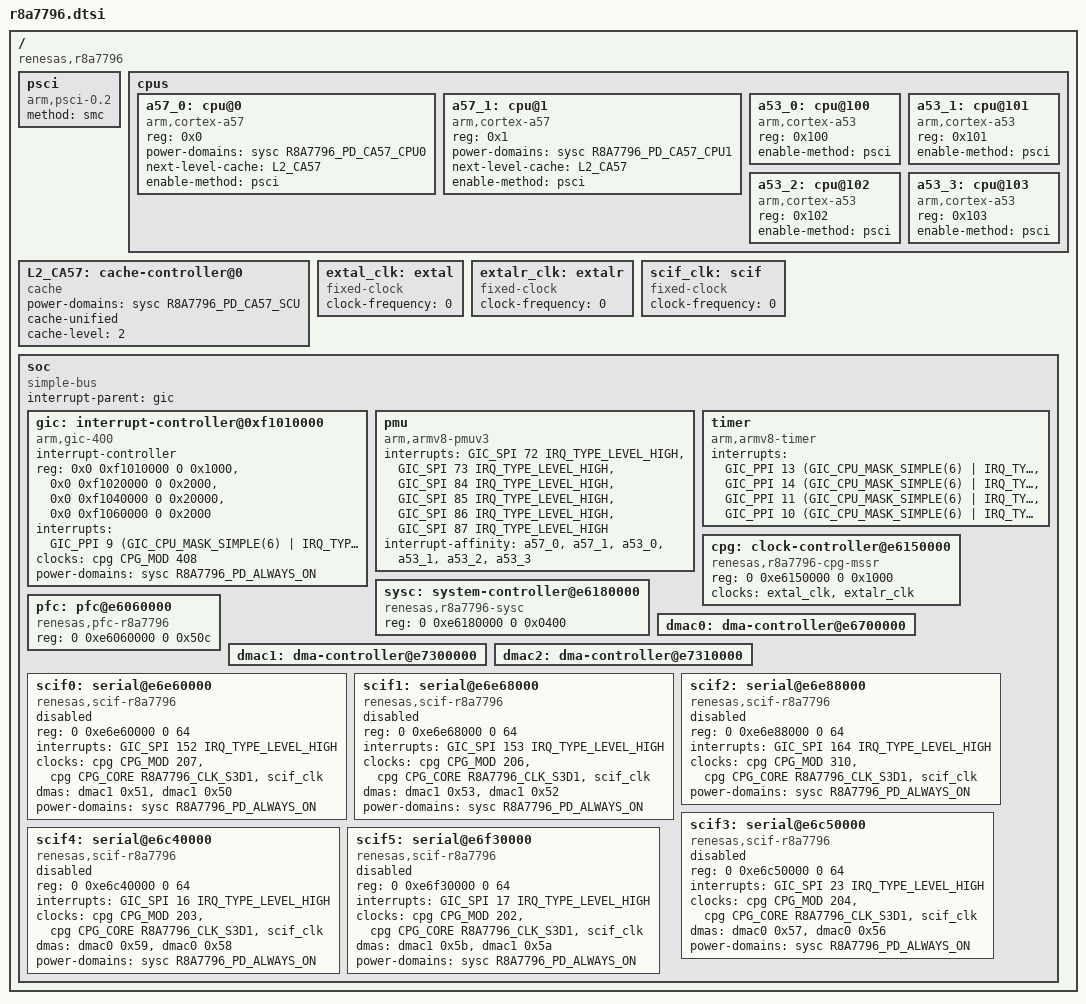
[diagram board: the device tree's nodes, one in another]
/*
 * Device Tree Source for the r8a7796 SoC
 *
 * Copyright (C) 2016 Renesas Electronics Corp.
 *
 * This file is licensed under the terms of the GNU General Public License
 * version 2.  This program is licensed "as is" without any warranty of any
 * kind, whether express or implied.
 */

#include <dt-bindings/clock/r8a7796-cpg-mssr.h>
#include <dt-bindings/interrupt-controller/arm-gic.h>
#include <dt-bindings/power/r8a7796-sysc.h>

/ {
	compatible = "renesas,r8a7796";
	#address-cells = <2>;
	#size-cells = <2>;

	psci {
		compatible = "arm,psci-0.2";
		method = "smc";
	};

	cpus {
		#address-cells = <1>;
		#size-cells = <0>;

		a57_0: cpu@0 {
			compatible = "arm,cortex-a57", "arm,armv8";
			reg = <0x0>;
			device_type = "cpu";
			power-domains = <&sysc R8A7796_PD_CA57_CPU0>;
			next-level-cache = <&L2_CA57>;
			enable-method = "psci";
		};

		a57_1: cpu@1 {
			compatible = "arm,cortex-a57","arm,armv8";
			reg = <0x1>;
			device_type = "cpu";
			power-domains = <&sysc R8A7796_PD_CA57_CPU1>;
			next-level-cache = <&L2_CA57>;
			enable-method = "psci";
		};

		a53_0: cpu@100 {
			compatible = "arm,cortex-a53", "arm,armv8";
			reg = <0x100>;
			device_type = "cpu";
			enable-method = "psci";
		};

		a53_1: cpu@101 {
			compatible = "arm,cortex-a53","arm,armv8";
			reg = <0x101>;
			device_type = "cpu";
			enable-method = "psci";
		};

		a53_2: cpu@102 {
			compatible = "arm,cortex-a53","arm,armv8";
			reg = <0x102>;
			device_type = "cpu";
			enable-method = "psci";
		};

		a53_3: cpu@103 {
			compatible = "arm,cortex-a53","arm,armv8";
			reg = <0x103>;
			device_type = "cpu";
			enable-method = "psci";
		};
	};

	L2_CA57: cache-controller@0 {
		compatible = "cache";
		power-domains = <&sysc R8A7796_PD_CA57_SCU>;
		cache-unified;
		cache-level = <2>;
	};

	extal_clk: extal {
		compatible = "fixed-clock";
		#clock-cells = <0>;
		/* This value must be overridden by the board */
		clock-frequency = <0>;
	};

	extalr_clk: extalr {
		compatible = "fixed-clock";
		#clock-cells = <0>;
		/* This value must be overridden by the board */
		clock-frequency = <0>;
	};

	/* External SCIF clock - to be overridden by boards that provide it */
	scif_clk: scif {
		compatible = "fixed-clock";
		#clock-cells = <0>;
		clock-frequency = <0>;
	};

	soc {
		compatible = "simple-bus";
		interrupt-parent = <&gic>;

		#address-cells = <2>;
		#size-cells = <2>;
		ranges;

		gic: interrupt-controller@0xf1010000 {
			compatible = "arm,gic-400";
			#interrupt-cells = <3>;
			#address-cells = <0>;
			interrupt-controller;
			reg = <0x0 0xf1010000 0 0x1000>,
			      <0x0 0xf1020000 0 0x2000>,
			      <0x0 0xf1040000 0 0x20000>,
			      <0x0 0xf1060000 0 0x2000>;
			interrupts = <GIC_PPI 9
					(GIC_CPU_MASK_SIMPLE(6) | IRQ_TYPE_LEVEL_HIGH)>;
			clocks = <&cpg CPG_MOD 408>;
			clock-names = "clk";
			power-domains = <&sysc R8A7796_PD_ALWAYS_ON>;
		};

		pmu {
			compatible = "arm,armv8-pmuv3";
			interrupts = <GIC_SPI 72 IRQ_TYPE_LEVEL_HIGH>,
				     <GIC_SPI 73 IRQ_TYPE_LEVEL_HIGH>,
				     <GIC_SPI 84 IRQ_TYPE_LEVEL_HIGH>,
				     <GIC_SPI 85 IRQ_TYPE_LEVEL_HIGH>,
				     <GIC_SPI 86 IRQ_TYPE_LEVEL_HIGH>,
				     <GIC_SPI 87 IRQ_TYPE_LEVEL_HIGH>;
			interrupt-affinity = <&a57_0>,
					     <&a57_1>,
					     <&a53_0>,
					     <&a53_1>,
					     <&a53_2>,
					     <&a53_3>;
		};

		timer {
			compatible = "arm,armv8-timer";
			interrupts = <GIC_PPI 13
					(GIC_CPU_MASK_SIMPLE(6) | IRQ_TYPE_LEVEL_LOW)>,
				     <GIC_PPI 14
					(GIC_CPU_MASK_SIMPLE(6) | IRQ_TYPE_LEVEL_LOW)>,
				     <GIC_PPI 11
					(GIC_CPU_MASK_SIMPLE(6) | IRQ_TYPE_LEVEL_LOW)>,
				     <GIC_PPI 10
					(GIC_CPU_MASK_SIMPLE(6) | IRQ_TYPE_LEVEL_LOW)>;
		};

		cpg: clock-controller@e6150000 {
			compatible = "renesas,r8a7796-cpg-mssr";
			reg = <0 0xe6150000 0 0x1000>;
			clocks = <&extal_clk>, <&extalr_clk>;
			clock-names = "extal", "extalr";
			#clock-cells = <2>;
			#power-domain-cells = <0>;
		};

		sysc: system-controller@e6180000 {
			compatible = "renesas,r8a7796-sysc";
			reg = <0 0xe6180000 0 0x0400>;
			#power-domain-cells = <1>;
		};

		pfc: pfc@e6060000 {
			compatible = "renesas,pfc-r8a7796";
			reg = <0 0xe6060000 0 0x50c>;
		};

		dmac0: dma-controller@e6700000 {
			/* Empty node for now */
		};

		dmac1: dma-controller@e7300000 {
			/* Empty node for now */
		};

		dmac2: dma-controller@e7310000 {
			/* Empty node for now */
		};

		scif0: serial@e6e60000 {
			compatible = "renesas,scif-r8a7796",
				     "renesas,rcar-gen3-scif", "renesas,scif";
			reg = <0 0xe6e60000 0 64>;
			interrupts = <GIC_SPI 152 IRQ_TYPE_LEVEL_HIGH>;
			clocks = <&cpg CPG_MOD 207>,
				 <&cpg CPG_CORE R8A7796_CLK_S3D1>,
				 <&scif_clk>;
			clock-names = "fck", "brg_int", "scif_clk";
			dmas = <&dmac1 0x51>, <&dmac1 0x50>;
			dma-names = "tx", "rx";
			power-domains = <&sysc R8A7796_PD_ALWAYS_ON>;
			status = "disabled";
		};

		scif1: serial@e6e68000 {
			compatible = "renesas,scif-r8a7796",
				     "renesas,rcar-gen3-scif", "renesas,scif";
			reg = <0 0xe6e68000 0 64>;
			interrupts = <GIC_SPI 153 IRQ_TYPE_LEVEL_HIGH>;
			clocks = <&cpg CPG_MOD 206>,
				 <&cpg CPG_CORE R8A7796_CLK_S3D1>,
				 <&scif_clk>;
			clock-names = "fck", "brg_int", "scif_clk";
			dmas = <&dmac1 0x53>, <&dmac1 0x52>;
			dma-names = "tx", "rx";
			power-domains = <&sysc R8A7796_PD_ALWAYS_ON>;
			status = "disabled";
		};

		scif2: serial@e6e88000 {
			compatible = "renesas,scif-r8a7796",
				     "renesas,rcar-gen3-scif", "renesas,scif";
			reg = <0 0xe6e88000 0 64>;
			interrupts = <GIC_SPI 164 IRQ_TYPE_LEVEL_HIGH>;
			clocks = <&cpg CPG_MOD 310>,
				 <&cpg CPG_CORE R8A7796_CLK_S3D1>,
				 <&scif_clk>;
			clock-names = "fck", "brg_int", "scif_clk";
			power-domains = <&sysc R8A7796_PD_ALWAYS_ON>;
			status = "disabled";
		};

		scif3: serial@e6c50000 {
			compatible = "renesas,scif-r8a7796",
				     "renesas,rcar-gen3-scif", "renesas,scif";
			reg = <0 0xe6c50000 0 64>;
			interrupts = <GIC_SPI 23 IRQ_TYPE_LEVEL_HIGH>;
			clocks = <&cpg CPG_MOD 204>,
				 <&cpg CPG_CORE R8A7796_CLK_S3D1>,
				 <&scif_clk>;
			clock-names = "fck", "brg_int", "scif_clk";
			dmas = <&dmac0 0x57>, <&dmac0 0x56>;
			dma-names = "tx", "rx";
			power-domains = <&sysc R8A7796_PD_ALWAYS_ON>;
			status = "disabled";
		};

		scif4: serial@e6c40000 {
			compatible = "renesas,scif-r8a7796",
				     "renesas,rcar-gen3-scif", "renesas,scif";
			reg = <0 0xe6c40000 0 64>;
			interrupts = <GIC_SPI 16 IRQ_TYPE_LEVEL_HIGH>;
			clocks = <&cpg CPG_MOD 203>,
				 <&cpg CPG_CORE R8A7796_CLK_S3D1>,
				 <&scif_clk>;
			clock-names = "fck", "brg_int", "scif_clk";
			dmas = <&dmac0 0x59>, <&dmac0 0x58>;
			dma-names = "tx", "rx";
			power-domains = <&sysc R8A7796_PD_ALWAYS_ON>;
			status = "disabled";
		};

		scif5: serial@e6f30000 {
			compatible = "renesas,scif-r8a7796",
				     "renesas,rcar-gen3-scif", "renesas,scif";
			reg = <0 0xe6f30000 0 64>;
			interrupts = <GIC_SPI 17 IRQ_TYPE_LEVEL_HIGH>;
			clocks = <&cpg CPG_MOD 202>,
				 <&cpg CPG_CORE R8A7796_CLK_S3D1>,
				 <&scif_clk>;
			clock-names = "fck", "brg_int", "scif_clk";
			dmas = <&dmac1 0x5b>, <&dmac1 0x5a>;
			dma-names = "tx", "rx";
			power-domains = <&sysc R8A7796_PD_ALWAYS_ON>;
			status = "disabled";
		};
	};
};
